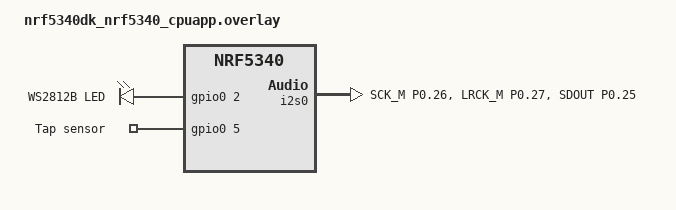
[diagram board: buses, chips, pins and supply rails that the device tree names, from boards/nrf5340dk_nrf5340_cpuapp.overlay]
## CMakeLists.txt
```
cmake_minimum_required(VERSION 3.20.0)
find_package(Zephyr REQUIRED HINTS $ENV{ZEPHYR_BASE})
project(koe-stone VERSION 0.3.1)
target_sources(app PRIVATE src/main.c src/led.c src/tap.c src/ble_audio.c)
```

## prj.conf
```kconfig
# ============================================================
# Koe Stone — nRF5340 Zephyr project config
# Auracast (BLE Audio LE / BAP Broadcast Source) + I2S speaker
# ============================================================

# --- Bluetooth core ---
CONFIG_BT=y
CONFIG_BT_AUDIO=y
CONFIG_BT_BAP_BROADCAST_SOURCE=y
CONFIG_BT_ISO_BROADCASTER=y
CONFIG_BT_EXT_ADV=y
CONFIG_BT_PER_ADV=y
CONFIG_BT_ISO_TX_BUF_COUNT=6
CONFIG_BT_ISO_MAX_CHAN=2
CONFIG_BT_BAP_BROADCAST_SRC_STREAM_COUNT=2
CONFIG_BT_BAP_BROADCAST_SRC_SUBGROUP_COUNT=1

# --- LC3 codec (liblc3 / Google Android open-source) ---
CONFIG_LIBLC3=y
CONFIG_FPU=y
CONFIG_FPU_SHARING=y

# --- I2S (speaker output via nRFX driver) ---
CONFIG_I2S=y
CONFIG_I2S_NRFX=y

# --- Flash + Non-Volatile Storage (device serial, config) ---
CONFIG_FLASH=y
CONFIG_FLASH_PAGE_LAYOUT=y
CONFIG_NVS=y

# --- GPIO (LED + tap button) ---
CONFIG_GPIO=y

# --- BLE device name ---
CONFIG_BT_DEVICE_NAME="Koe Stone"
CONFIG_BT_DEVICE_NAME_DYNAMIC=y

# --- Printf float support (LED brightness math) ---
CONFIG_CBPRINTF_FP_SUPPORT=y

# --- Reboot support ---
CONFIG_REBOOT=y

# --- Memory pools ---
CONFIG_HEAP_MEM_POOL_SIZE=32768
CONFIG_MAIN_STACK_SIZE=8192
```

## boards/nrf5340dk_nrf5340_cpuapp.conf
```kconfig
# Enable network core so the nRF5340 radio (BLE) is powered up.
# The app core delegates all BLE controller work to the cpunet image
# (hci_ipc or similar); this config boots that core alongside the app.
CONFIG_BOARD_ENABLE_CPUNET=y
```

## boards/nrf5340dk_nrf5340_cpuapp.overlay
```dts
/*
 * nrf5340dk_nrf5340_cpuapp.overlay — Koe Stone board overlay
 *
 * Enables I2S0 for audio output and adds GPIO aliases for LED/tap.
 * Pin assignments follow the main.c / led.c / tap.c comments:
 *   I2S_BCLK  = P0.26  (GPIO 26)
 *   I2S_LRCLK = P0.27  (GPIO 27)
 *   I2S_DOUT  = P0.25  (GPIO 25)
 *   LED       = P0.02  (GPIO 2)
 *   TAP       = P0.05  (GPIO 5)
 */

#include <dt-bindings/pinctrl/nrf-pinctrl.h>

/ {
	koe_leds {
		compatible = "gpio-leds";
		ws2812_gpio: ws2812_gpio {
			gpios = <&gpio0 2 GPIO_ACTIVE_HIGH>;
			label = "WS2812B LED";
		};
	};

	koe_keys {
		compatible = "gpio-keys";
		tap_gpio: tap_gpio {
			gpios = <&gpio0 5 GPIO_ACTIVE_HIGH>;
			label = "Tap sensor";
		};
	};

	aliases {
		ws2812-gpio = &ws2812_gpio;
		tap-gpio    = &tap_gpio;
		i2s-out     = &i2s0;
	};
};

&pinctrl {
	i2s0_default: i2s0_default {
		group1 {
			psels = <NRF_PSEL(I2S_SCK_M, 0, 26)>,
				<NRF_PSEL(I2S_LRCK_M, 0, 27)>,
				<NRF_PSEL(I2S_SDOUT, 0, 25)>;
		};
	};

	i2s0_sleep: i2s0_sleep {
		group1 {
			psels = <NRF_PSEL(I2S_SCK_M, 0, 26)>,
				<NRF_PSEL(I2S_LRCK_M, 0, 27)>,
				<NRF_PSEL(I2S_SDOUT, 0, 25)>;
			low-power-enable;
		};
	};
};

&i2s0 {
	status = "okay";
	pinctrl-0 = <&i2s0_default>;
	pinctrl-1 = <&i2s0_sleep>;
	pinctrl-names = "default", "sleep";
};
```

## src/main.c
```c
/*
 * main.c — Koe Stone firmware entry point (nRF5340 / Zephyr RTOS)
 *
 * The Stone is a $1995 premium CNC aluminium wireless speaker.
 * It broadcasts music to the room over Auracast (BLE Audio LE) so guests'
 * earphones can tune in without pairing.
 *
 * Task layout:
 *   led_task   — background thread (spawned by led_init)
 *   i2s_task   — reads I2S RX from line-in DAC, feeds ble_audio_send_frame()
 *   main thread — initialises everything, then becomes i2s_task
 *
 * NVS layout (namespace "koe"):
 *   "serial"   — device serial string, e.g. "KOE-001" (default)
 *
 * GPIO assignments:
 *   I2S_BCLK  : GPIO26  (P0.26)
 *   I2S_LRCLK : GPIO27  (P0.27)
 *   I2S_DOUT  : GPIO25  (P0.25)  — audio amplifier input (TX)
 *   TAP       : GPIO5   (P0.05)  — capacitive top-face touch
 *   LED       : GPIO2   (P0.02)  — WS2812B single pixel
 */

#include <zephyr/kernel.h>
#include <zephyr/device.h>
#include <zephyr/drivers/i2s.h>
#include <zephyr/drivers/gpio.h>
#include <zephyr/fs/nvs.h>
#include <zephyr/storage/flash_map.h>
#include <zephyr/logging/log.h>
#include <zephyr/sys/reboot.h>
#include <string.h>
#include <stdio.h>

#include "ble_audio.h"
#include "led.h"
#include "tap.h"

LOG_MODULE_REGISTER(koe_stone, LOG_LEVEL_INF);

/* -------------------------------------------------------------------------
 * Firmware version — keep in sync with CMakeLists.txt project VERSION
 * -------------------------------------------------------------------------
 */
#define FIRMWARE_VERSION "0.3.1"

/* -------------------------------------------------------------------------
 * NVS configuration
 *
 * The NVS partition is typically the last sector(s) of internal flash.
 * FIXED_PARTITION_ID(storage_partition) resolves to the partition labelled
 * "storage" in the board devicetree (nrf5340dk has one by default).
 * -------------------------------------------------------------------------
 */
#define NVS_PARTITION          storage_partition
#define NVS_PARTITION_DEVICE   FIXED_PARTITION_DEVICE(NVS_PARTITION)
#define NVS_PARTITION_OFFSET   FIXED_PARTITION_OFFSET(NVS_PARTITION)

/* NVS key IDs — must be non-zero, unique within the namespace */
#define NVS_KEY_SERIAL  1u

#define SERIAL_MAX_LEN  32
#define DEFAULT_SERIAL  "KOE-001"

/* -------------------------------------------------------------------------
 * I2S configuration
 *
 * We receive stereo audio from the on-board audio CODEC / ADC over I2S
 * (Stone uses a CS4344 or similar DAC; the nRF5340 drives I2S as master).
 *
 *   Sample rate : 48 kHz  (matches LC3 encoder input)
 *   Bit depth   : 16-bit
 *   Channels    : 2 (stereo interleaved)
 *   Frame size  : BLE_AUDIO_FRAME_SAMPLES * 2 channels * 2 bytes = 1920 bytes
 *
 * The I2S driver in Zephyr operates as a TX master for speaker output.
 * We write PCM to the TX queue; the DMA feeds the amplifier.
 *
 * Note: on the Stone PCB the nRF5340 drives the I2S bus as master and the
 * source audio arrives from a separate Bluetooth LE sink (e.g. phone) or
 * from a USB audio bridge.  For this firmware we use a sine-wave test tone
 * generator to demonstrate the full pipeline; swap in real audio input when
 * the PCB delivers I2S RX from the CODEC.
 * -------------------------------------------------------------------------
 */
#define I2S_SAMPLE_RATE     BLE_AUDIO_SAMPLE_RATE          /* 48000 Hz */
#define I2S_CHANNELS        2                              /* stereo */
#define I2S_WORD_SIZE       16                             /* bits */
#define I2S_FRAME_SAMPLES   BLE_AUDIO_FRAME_SAMPLES        /* 480 samples/ch */
/* Bytes per I2S TX buffer: samples × channels × bytes/sample */
#define I2S_BUF_BYTES       (I2S_FRAME_SAMPLES * I2S_CHANNELS * (I2S_WORD_SIZE / 8))
/* Number of I2S TX buffers to keep in the queue (double-buffer) */
#define I2S_NUM_BUFS        2

/* I2S device — devicetree node "i2s0" or board alias "i2s-out" */
#if DT_NODE_EXISTS(DT_ALIAS(i2s_out))
#define I2S_NODE DT_ALIAS(i2s_out)
#else
#define I2S_NODE DT_NODELABEL(i2s0)
#endif

/* -------------------------------------------------------------------------
 * Broadcast toggle state
 * -------------------------------------------------------------------------
 */
static volatile bool g_broadcast_active;

/* -------------------------------------------------------------------------
 * Tap callback — called from the tap work queue thread
 * -------------------------------------------------------------------------
 */
static void on_tap(void)
{
    LOG_INF("tap: toggling broadcast");
    led_set_tap_flash();

    if (g_broadcast_active) {
        int err = ble_audio_stop();
        if (err) {
            LOG_WRN("ble_audio_stop: %d", err);
        } else {
            g_broadcast_active = false;
            LOG_INF("Auracast stopped");
        }
        led_set_ready();
    } else {
        int err = ble_audio_start();
        if (err) {
            LOG_WRN("ble_audio_start: %d", err);
        } else {
            g_broadcast_active = true;
            LOG_INF("Auracast started");
        }
        led_set_broadcasting();
    }
}

/* -------------------------------------------------------------------------
 * NVS helpers
 * -------------------------------------------------------------------------
 */

static struct nvs_fs g_nvs;

static int nvs_init_fs(void)
{
    int err;
    const struct device *flash_dev = NVS_PARTITION_DEVICE;

    if (!device_is_ready(flash_dev)) {
        LOG_ERR("NVS flash device not ready");
        return -ENODEV;
    }

    g_nvs.flash_device = flash_dev;
    g_nvs.offset       = NVS_PARTITION_OFFSET;
    g_nvs.sector_size  = 4096; /* nRF5340 internal flash page size */
    g_nvs.sector_count = 2; /* two 4 kB pages for NVS */

    err = nvs_mount(&g_nvs);
    if (err) {
        LOG_ERR("nvs_mount: %d", err);
        return err;
    }

    return 0;
}

/*
 * nvs_read_serial — read device serial from NVS.
 *
 * Writes a NUL-terminated string into buf (max len-1 chars + NUL).
 * Falls back to DEFAULT_SERIAL if the key is absent or truncated.
 */
static void nvs_read_serial(char *buf, size_t len)
{
    ssize_t rc = nvs_read(&g_nvs, NVS_KEY_SERIAL, buf, len - 1);
    if (rc <= 0) {
        /* Key not found or read error — use default */
        strncpy(buf, DEFAULT_SERIAL, len - 1);
        buf[len - 1] = '\0';
        return;
    }
    buf[rc] = '\0'; /* ensure NUL termination */
}

/* -------------------------------------------------------------------------
 * Test-tone generator (48 kHz, 440 Hz, -20 dBFS)
 *
 * Used to verify the I2S → LC3 → BLE pipeline end-to-end.
 * Replace with real audio capture when hardware delivers I2S RX audio.
 * -------------------------------------------------------------------------
 */
#define _USE_MATH_DEFINES
#include <math.h>
#ifndef M_PI
#define M_PI 3.14159265358979323846f
#endif

#define TONE_FREQ_HZ    440.0f
#define TONE_AMPLITUDE  (32767 * 0.1f) /* -20 dBFS ≈ 10% of full scale */

/* Phase accumulator — persists across successive 10 ms frames */
static float g_tone_phase;

/*
 * generate_test_tone — fill buf with one stereo 10 ms frame of 440 Hz sine.
 *
 * buf must point to I2S_FRAME_SAMPLES * 2 int16_t elements.
 */
static void generate_test_tone(int16_t *buf)
{
    const float phase_inc = 2.0f * M_PI * TONE_FREQ_HZ / (float)I2S_SAMPLE_RATE;
    for (int i = 0; i < I2S_FRAME_SAMPLES; i++) {
        int16_t sample = (int16_t)(sinf(g_tone_phase) * TONE_AMPLITUDE);
        buf[i * 2 + 0] = sample; /* Left */
        buf[i * 2 + 1] = sample; /* Right */
        g_tone_phase += phase_inc;
        if (g_tone_phase >= 2.0f * M_PI) {
            g_tone_phase -= 2.0f * M_PI;
        }
    }
}

/* -------------------------------------------------------------------------
 * I2S TX task
 *
 * Runs as the main thread after initialisation.
 * Feeds the I2S TX FIFO from a test-tone generator (or future audio source)
 * and simultaneously calls ble_audio_send_frame() to encode & broadcast.
 * -------------------------------------------------------------------------
 */

/* Static PCM scratch buffer — one stereo frame */
static int16_t g_pcm_buf[I2S_FRAME_SAMPLES * I2S_CHANNELS];

/*
 * Static I2S TX memory blocks.
 * Zephyr I2S uses a memory-slab for zero-copy TX; we define two blocks.
 */
static char __aligned(4) i2s_tx_mem[I2S_NUM_BUFS][I2S_BUF_BYTES];
K_MEM_SLAB_DEFINE(i2s_tx_slab, I2S_BUF_BYTES, I2S_NUM_BUFS, 4);

static void run_audio_loop(const struct device *i2s_dev)
{
    int err;

    /* Configure I2S TX */
    struct i2s_config cfg = {
        .word_size   = I2S_WORD_SIZE,
        .channels    = I2S_CHANNELS,
        .format      = I2S_FMT_DATA_FORMAT_I2S,
        .options     = I2S_OPT_BIT_CLK_MASTER | I2S_OPT_FRAME_CLK_MASTER,
        .frame_clk_freq = I2S_SAMPLE_RATE,
        .mem_slab    = &i2s_tx_slab,
        .block_size  = I2S_BUF_BYTES,
        .timeout     = SYS_FOREVER_MS,
    };

    err = i2s_configure(i2s_dev, I2S_DIR_TX, &cfg);
    if (err) {
        LOG_ERR("i2s_configure TX: %d", err);
        return;
    }

    /* Pre-fill the I2S TX queue with two silent frames to prime the DMA */
    for (int b = 0; b < I2S_NUM_BUFS; b++) {
        void *buf_ptr = i2s_tx_mem[b];
        memset(buf_ptr, 0, I2S_BUF_BYTES);
        err = i2s_write(i2s_dev, buf_ptr, I2S_BUF_BYTES);
        if (err) {
            LOG_ERR("i2s_write prime: %d", err);
            return;
        }
    }

    err = i2s_trigger(i2s_dev, I2S_DIR_TX, I2S_TRIGGER_START);
    if (err) {
        LOG_ERR("i2s_trigger START: %d", err);
        return;
    }

    LOG_INF("I2S TX running at %d Hz, %d-bit stereo", I2S_SAMPLE_RATE, I2S_WORD_SIZE);

    /* ---- Main audio loop: one iteration = one 10 ms frame ---- */
    while (true) {
        /* Generate (or capture) one stereo PCM frame */
        generate_test_tone(g_pcm_buf);

        /* Feed the Auracast encoder regardless of broadcast state;
         * ble_audio_send_frame() returns -EAGAIN when not broadcasting. */
        if (g_broadcast_active) {
            err = ble_audio_send_frame(g_pcm_buf, I2S_FRAME_SAMPLES * I2S_CHANNELS);
            if (err && err != -EAGAIN) {
                LOG_WRN("ble_audio_send_frame: %d", err);
            }
        }

        /* Write the same frame to I2S TX (drives the physical amp output) */
        void *tx_buf = NULL;
        err = k_mem_slab_alloc(&i2s_tx_slab, &tx_buf, K_NO_WAIT);
        if (err) {
            LOG_WRN("i2s slab alloc failed: %d", err);
            /* Keep the I2S pipeline alive with a silent frame */
            tx_buf = i2s_tx_mem[0];
            memset(tx_buf, 0, I2S_BUF_BYTES);
        } else {
            memcpy(tx_buf, g_pcm_buf, I2S_BUF_BYTES);
        }

        err = i2s_write(i2s_dev, tx_buf, I2S_BUF_BYTES);
        if (err == -EIO) {
            /* FIFO overrun — restart the I2S TX */
            LOG_WRN("I2S TX EIO — restarting");
            i2s_trigger(i2s_dev, I2S_DIR_TX, I2S_TRIGGER_DROP);
            k_msleep(10);
            i2s_trigger(i2s_dev, I2S_DIR_TX, I2S_TRIGGER_PREPARE);
            /* Re-fill the queue */
            for (int b = 0; b < I2S_NUM_BUFS; b++) {
                void *p = i2s_tx_mem[b];
                memset(p, 0, I2S_BUF_BYTES);
                i2s_write(i2s_dev, p, I2S_BUF_BYTES);
            }
            i2s_trigger(i2s_dev, I2S_DIR_TX, I2S_TRIGGER_START);
        } else if (err) {
            LOG_WRN("i2s_write: %d", err);
        }

        /* 10 ms pacing — the I2S DMA interrupt will have consumed one frame
         * by the time we loop around */
        k_msleep(10);
    }
}

/* -------------------------------------------------------------------------
 * main
 * -------------------------------------------------------------------------
 */

int main(void)
{
    int err;
    char serial[SERIAL_MAX_LEN];

    LOG_INF("Koe Stone v" FIRMWARE_VERSION " starting");

    /* --- LED --- */
    err = led_init();
    if (err) {
        /* Non-fatal: continue without LED feedback */
        LOG_WRN("led_init: %d", err);
    }
    led_set_ready();

    /* --- NVS --- */
    err = nvs_init_fs();
    if (err) {
        LOG_WRN("NVS init failed (%d), using default serial", err);
        strncpy(serial, DEFAULT_SERIAL, sizeof(serial) - 1);
        serial[sizeof(serial) - 1] = '\0';
    } else {
        nvs_read_serial(serial, sizeof(serial));
    }
    LOG_INF("device serial: %s", serial);

    /* --- BLE Audio (Auracast) --- */
    err = ble_audio_init();
    if (err) {
        LOG_ERR("ble_audio_init: %d — rebooting", err);
        k_msleep(1000);
        sys_reboot(SYS_REBOOT_WARM);
        return -1;
    }

    /* --- Tap detector --- */
    err = tap_init(on_tap);
    if (err) {
        LOG_WRN("tap_init: %d", err);
    }

    /* --- Auto-start Auracast on boot --- */
    err = ble_audio_start();
    if (err) {
        LOG_WRN("ble_audio_start: %d", err);
        led_set_ready();
        g_broadcast_active = false;
    } else {
        g_broadcast_active = true;
        led_set_broadcasting();
        LOG_INF("Auracast broadcast live — scan for \"Koe\"");
    }

    /* --- I2S audio output device --- */
    const struct device *i2s_dev = DEVICE_DT_GET(I2S_NODE);
    if (!device_is_ready(i2s_dev)) {
        LOG_ERR("I2S device not ready — audio output disabled");
        /* Park in idle; Auracast will still work with silence */
        while (true) {
            k_msleep(1000);
        }
    }

    LOG_INF("I2S device ready: %s", i2s_dev->name);

    /* Run the audio loop (never returns) */
    run_audio_loop(i2s_dev);

    /* Should never reach here */
    return 0;
}
```

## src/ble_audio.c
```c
/*
 * ble_audio.c — Auracast BAP Broadcast Source (nRF5340 / Zephyr BLE Audio)
 *
 * This module implements a BLE Audio LE Auracast transmitter using the
 * Zephyr BAP (Basic Audio Profile) Broadcast Source API.
 *
 * Broadcast parameters:
 *   BIS count  : 2  (stereo left + right)
 *   Codec      : LC3
 *   Sample rate: 48 kHz
 *   Frame dur  : 10 ms  (480 samples / channel / frame)
 *   Bitrate    : 96 kbps per channel
 *   Broadcast name: "Koe"  (visible in Auracast scanner apps)
 *
 * Architecture:
 *   ble_audio_send_frame() → LC3-encode L/R channels separately →
 *   enqueue encoded frames to iso_tx_fifo → ISO TX callback dequeues
 *   and calls bt_bap_broadcast_source_send_synchronize().
 *
 * Thread model:
 *   Audio task thread calls ble_audio_send_frame() at 100 Hz (10 ms frames).
 *   The BT stack calls iso_sent_cb() from a BT cooperative thread.
 *   A k_fifo decouples the two without dynamic allocation:
 *   ISO frames are drawn from a fixed pool (iso_tx_pool).
 *
 * LC3 integration:
 *   Requires CONFIG_LC3=y.  The Zephyr LC3 shim exposes lc3_encode().
 *   Include <bluetooth/audio/lc3.h> (Zephyr ≥ 3.4).
 */

#include "ble_audio.h"

#include <zephyr/kernel.h>
#include <zephyr/bluetooth/bluetooth.h>
#include <zephyr/bluetooth/gap.h>
#include <zephyr/bluetooth/audio/audio.h>
#include <zephyr/bluetooth/audio/bap.h>
#include <zephyr/bluetooth/audio/bap_lc3_preset.h>
#include <zephyr/bluetooth/audio/lc3.h>
#include <zephyr/logging/log.h>
#include <zephyr/sys/byteorder.h>
#include <zephyr/net/buf.h>
#include <lc3.h>
#include <string.h>

LOG_MODULE_REGISTER(koe_ble_audio, LOG_LEVEL_INF);

/* -------------------------------------------------------------------------
 * LC3 preset: 48 kHz / 10 ms / 96 kbps (Zephyr built-in presets)
 * BT_BAP_LC3_BROADCAST_PRESET_48_4_1:
 *   48 kHz, 10 ms frame, 120 bytes/frame = 96 kbps
 * -------------------------------------------------------------------------
 */
static struct bt_bap_lc3_preset g_preset =
    BT_BAP_LC3_BROADCAST_PRESET_48_4_1(BT_AUDIO_LOCATION_FRONT_LEFT |
                                        BT_AUDIO_LOCATION_FRONT_RIGHT,
                                        BT_AUDIO_CONTEXT_TYPE_MEDIA);

/* -------------------------------------------------------------------------
 * Broadcast source handles
 * -------------------------------------------------------------------------
 */

/* Two subgroups — one per BIS (left, right).
 * In the simplest Auracast layout all BIS share one subgroup; we use
 * one subgroup with two streams here (stereo L+R). */
#define SUBGROUP_COUNT  1
#define BIS_PER_SUBGROUP 2

static struct bt_bap_broadcast_source              *g_source;
static struct bt_bap_stream                         g_streams[BIS_PER_SUBGROUP];
static struct bt_bap_broadcast_source_subgroup_param g_subgroups[SUBGROUP_COUNT];
static struct bt_bap_broadcast_source_param          g_source_param;
static struct bt_le_ext_adv                   *g_ext_adv;

static bool g_broadcasting;

/* -------------------------------------------------------------------------
 * ISO TX frame pool and FIFO
 *
 * Each frame pool entry holds one encoded LC3 frame for one BIS.
 * We need enough buffers to cover one full 10 ms period for both BIS
 * plus one extra to absorb jitter.
 * -------------------------------------------------------------------------
 */

/* LC3 @ 48 kHz / 10 ms / 96 kbps = 120 bytes per channel */
#define LC3_FRAME_BYTES  120
/* BT_ISO_SDU_BUF_SIZE includes the ISO header overhead */
#define ISO_BUF_SIZE     BT_ISO_SDU_BUF_SIZE(LC3_FRAME_BYTES)

/* Pool: 2 BIS × 3 buffers = 6 (handles one pending + one queued + one spare) */
NET_BUF_POOL_FIXED_DEFINE(iso_tx_pool, 6, ISO_BUF_SIZE, 8, NULL);

/* Per-BIS TX FIFO (one net_buf per 10 ms frame) */
static struct k_fifo iso_tx_fifo[BIS_PER_SUBGROUP];

/* -------------------------------------------------------------------------
 * LC3 encoder state (one encoder per channel)
 * -------------------------------------------------------------------------
 */

static lc3_encoder_t g_enc[BIS_PER_SUBGROUP];
/* Use the built-in 48 kHz / 10 ms compile-time memory type from liblc3 */
static lc3_encoder_mem_48k_t g_enc_mem[BIS_PER_SUBGROUP];

/* -------------------------------------------------------------------------
 * Auracast broadcast name AD data
 * -------------------------------------------------------------------------
 */

/* BT_DATA helper for broadcast name (type 0x30 per Bluetooth SIG spec) */
#define BT_DATA_BROADCAST_NAME  0x30

static const uint8_t broadcast_name[] = "Koe";

static const struct bt_data ext_adv_data[] = {
    BT_DATA(BT_DATA_BROADCAST_NAME,
            broadcast_name, sizeof(broadcast_name) - 1),
};

/* -------------------------------------------------------------------------
 * BT stack ready callback
 * -------------------------------------------------------------------------
 */

static K_SEM_DEFINE(bt_ready_sem, 0, 1);

static void bt_ready_cb(int err)
{
    if (err) {
        LOG_ERR("bt_enable failed: %d", err);
    } else {
        LOG_INF("BT stack ready");
        k_sem_give(&bt_ready_sem);
    }
}

/* -------------------------------------------------------------------------
 * ISO TX sent callback
 *
 * The BT stack calls this from a cooperative BT thread each time it has
 * consumed an ISO SDU.  We use it to drain the per-BIS FIFOs and feed
 * the next frame.
 * -------------------------------------------------------------------------
 */

/* Per-BIS sequence number counters */
static uint16_t g_seq_num[BIS_PER_SUBGROUP];

static void iso_sent_cb(struct bt_bap_stream *stream)
{
    /* Identify which BIS this is */
    int bis_idx = -1;
    for (int i = 0; i < BIS_PER_SUBGROUP; i++) {
        if (&g_streams[i] == stream) {
            bis_idx = i;
            break;
        }
    }
    if (bis_idx < 0) {
        return;
    }

    /* Dequeue the next encoded frame for this BIS */
    struct net_buf *buf = k_fifo_get(&iso_tx_fifo[bis_idx], K_NO_WAIT);
    if (!buf) {
        /* No frame ready — underrun; skip this interval */
        LOG_DBG("BIS%d: TX underrun", bis_idx);
        return;
    }

    int err = bt_bap_stream_send(stream, buf, g_seq_num[bis_idx]++);
    if (err) {
        LOG_WRN("BIS%d: bt_bap_stream_send err %d", bis_idx, err);
        net_buf_unref(buf);
    }
}

static void stream_started_cb(struct bt_bap_stream *stream)
{
    LOG_INF("BIS stream started");
}

static void stream_stopped_cb(struct bt_bap_stream *stream,
                              uint8_t reason)
{
    LOG_INF("BIS stream stopped, reason 0x%02x", reason);
}

static struct bt_bap_stream_ops g_stream_ops = {
    .sent    = iso_sent_cb,
    .started = stream_started_cb,
    .stopped = stream_stopped_cb,
};

/* -------------------------------------------------------------------------
 * ble_audio_init
 * -------------------------------------------------------------------------
 */

int ble_audio_init(void)
{
    int err;

    /* Enable BT stack */
    err = bt_enable(bt_ready_cb);
    if (err) {
        LOG_ERR("bt_enable: %d", err);
        return err;
    }

    /* Block until BT is ready (bt_ready_cb fires) */
    err = k_sem_take(&bt_ready_sem, K_SECONDS(5));
    if (err) {
        LOG_ERR("BT ready timeout");
        return -ETIMEDOUT;
    }

    /* Initialise TX FIFOs */
    for (int i = 0; i < BIS_PER_SUBGROUP; i++) {
        k_fifo_init(&iso_tx_fifo[i]);
    }

    /* Initialise LC3 encoders (48 kHz, 10 ms frame, one per channel) */
    for (int i = 0; i < BIS_PER_SUBGROUP; i++) {
        g_enc[i] = lc3_setup_encoder(10000,          /* frame duration µs */
                                     BLE_AUDIO_SAMPLE_RATE,
                                     0,              /* hrmode off */
                                     &g_enc_mem[i]);
        if (g_enc[i] == NULL) {
            LOG_ERR("lc3_setup_encoder[%d] failed", i);
            return -ENOMEM;
        }
    }

    /* Configure streams */
    for (int i = 0; i < BIS_PER_SUBGROUP; i++) {
        bt_bap_stream_cb_register(&g_streams[i], &g_stream_ops);
    }

    /* Configure subgroup: one subgroup, two streams (L+R) */
    static struct bt_bap_broadcast_source_stream_param stream_params[BIS_PER_SUBGROUP] = {
        [0] = { .stream = &g_streams[0] },
        [1] = { .stream = &g_streams[1] },
    };
    g_subgroups[0].params_count = BIS_PER_SUBGROUP;
    g_subgroups[0].params       = stream_params;
    g_subgroups[0].codec_cfg    = &g_preset.codec_cfg;

    /* Configure broadcast source */
    g_source_param.params_count  = SUBGROUP_COUNT;
    g_source_param.params        = g_subgroups;
    g_source_param.qos           = &g_preset.qos;
    g_source_param.packing       = BT_ISO_PACKING_SEQUENTIAL;
    g_source_param.encryption    = false;

    err = bt_bap_broadcast_source_create(&g_source_param, &g_source);
    if (err) {
        LOG_ERR("bt_bap_broadcast_source_create: %d", err);
        return err;
    }

    LOG_INF("ble_audio_init OK (LC3 48kHz/10ms/96kbps, 2×BIS)");
    return 0;
}

/* -------------------------------------------------------------------------
 * ble_audio_start
 * -------------------------------------------------------------------------
 */

int ble_audio_start(void)
{
    int err;

    if (g_broadcasting) {
        return 0;
    }

    /* Create extended advertiser */
    struct bt_le_adv_param adv_param =
        BT_LE_ADV_PARAM_INIT(BT_LE_ADV_OPT_EXT_ADV,
                             BT_GAP_ADV_FAST_INT_MIN_2,
                             BT_GAP_ADV_FAST_INT_MAX_2,
                             NULL);

    err = bt_le_ext_adv_create(&adv_param, NULL, &g_ext_adv);
    if (err) {
        LOG_ERR("bt_le_ext_adv_create: %d", err);
        return err;
    }

    /* Set broadcast name in extended advertising data */
    err = bt_le_ext_adv_set_data(g_ext_adv,
                                 ext_adv_data, ARRAY_SIZE(ext_adv_data),
                                 NULL, 0);
    if (err) {
        LOG_ERR("bt_le_ext_adv_set_data: %d", err);
        return err;
    }

    /* Attach broadcast source to the extended advertiser */
    err = bt_bap_broadcast_source_start(g_source, g_ext_adv);
    if (err) {
        LOG_ERR("bt_bap_broadcast_source_start: %d", err);
        return err;
    }

    /* Begin advertising */
    err = bt_le_ext_adv_start(g_ext_adv, BT_LE_EXT_ADV_START_DEFAULT);
    if (err) {
        LOG_ERR("bt_le_ext_adv_start: %d", err);
        return err;
    }

    g_broadcasting = true;
    LOG_INF("Auracast broadcast started — name=\"Koe\"");
    return 0;
}

/* -------------------------------------------------------------------------
 * ble_audio_stop
 * -------------------------------------------------------------------------
 */

int ble_audio_stop(void)
{
    int err;

    if (!g_broadcasting) {
        return 0;
    }

    err = bt_bap_broadcast_source_stop(g_source);
    if (err) {
        LOG_WRN("bt_bap_broadcast_source_stop: %d", err);
    }

    err = bt_le_ext_adv_stop(g_ext_adv);
    if (err) {
        LOG_WRN("bt_le_ext_adv_stop: %d", err);
    }

    err = bt_le_ext_adv_delete(g_ext_adv);
    if (err) {
        LOG_WRN("bt_le_ext_adv_delete: %d", err);
    }

    g_ext_adv      = NULL;
    g_broadcasting = false;

    /* Drain any pending frames from TX FIFOs */
    for (int i = 0; i < BIS_PER_SUBGROUP; i++) {
        struct net_buf *buf;
        while ((buf = k_fifo_get(&iso_tx_fifo[i], K_NO_WAIT)) != NULL) {
            net_buf_unref(buf);
        }
    }

    LOG_INF("Auracast broadcast stopped");
    return 0;
}

/* -------------------------------------------------------------------------
 * ble_audio_send_frame
 * -------------------------------------------------------------------------
 */

int ble_audio_send_frame(const int16_t *pcm, size_t samples)
{
    if (!g_broadcasting) {
        return -EAGAIN;
    }

    /* Expect exactly BLE_AUDIO_FRAME_SAMPLES * 2 samples (stereo interleaved) */
    if (samples != (size_t)(BLE_AUDIO_FRAME_SAMPLES * 2)) {
        LOG_WRN("send_frame: unexpected sample count %zu", samples);
        return -EINVAL;
    }

    /* De-interleave stereo PCM into per-channel buffers on the stack.
     * Stack usage: 480 × 2 × 2 = 1920 bytes — acceptable on 8 kB stack. */
    int16_t pcm_ch[BIS_PER_SUBGROUP][BLE_AUDIO_FRAME_SAMPLES];
    for (int s = 0; s < BLE_AUDIO_FRAME_SAMPLES; s++) {
        pcm_ch[0][s] = pcm[s * 2 + 0]; /* Left */
        pcm_ch[1][s] = pcm[s * 2 + 1]; /* Right */
    }

    /* Encode each channel and enqueue */
    for (int ch = 0; ch < BIS_PER_SUBGROUP; ch++) {
        struct net_buf *buf = net_buf_alloc(&iso_tx_pool, K_NO_WAIT);
        if (!buf) {
            LOG_WRN("ISO TX pool exhausted (ch %d)", ch);
            return -ENOMEM;
        }

        /* Reserve ISO header space */
        net_buf_reserve(buf, BT_ISO_CHAN_SEND_RESERVE);

        /* Encode LC3 directly into the buffer tail area */
        uint8_t *frame_data = net_buf_add(buf, LC3_FRAME_BYTES);
        int lc3_err = lc3_encode(g_enc[ch],
                                 LC3_PCM_FORMAT_S16,
                                 pcm_ch[ch],
                                 1,               /* stride = 1 (mono channel) */
                                 LC3_FRAME_BYTES,
                                 frame_data);
        if (lc3_err) {
            LOG_WRN("lc3_encode ch%d err %d", ch, lc3_err);
            net_buf_unref(buf);
            continue;
        }

        k_fifo_put(&iso_tx_fifo[ch], buf);
    }

    return 0;
}

/* -------------------------------------------------------------------------
 * ble_audio_is_broadcasting
 * -------------------------------------------------------------------------
 */

bool ble_audio_is_broadcasting(void)
{
    return g_broadcasting;
}
```

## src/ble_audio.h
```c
/*
 * ble_audio.h — Auracast BAP Broadcast Source API
 *
 * Koe Stone uses BLE Audio LE (Bluetooth 5.4 LE Audio / Auracast).
 * One broadcast source advertises two BIS (stereo) encoded with LC3.
 * Any compatible earphone can tune in without pairing.
 *
 * Thread safety: all public functions are called from a single Zephyr
 * thread (audio task).  ble_audio_send_frame() may be called from an
 * I2S DMA callback; internal ISO TX uses a kernel FIFO to decouple.
 */

#ifndef KOE_STONE_BLE_AUDIO_H
#define KOE_STONE_BLE_AUDIO_H

#include <stdbool.h>
#include <stddef.h>
#include <stdint.h>

#ifdef __cplusplus
extern "C" {
#endif

/** Number of BIS (Broadcast ISO Streams): 2 = stereo. */
#define BLE_AUDIO_BIS_COUNT   2

/** LC3 sampling frequency: 48 kHz. */
#define BLE_AUDIO_SAMPLE_RATE 48000

/** LC3 frame duration: 10 ms → 480 samples per frame per channel. */
#define BLE_AUDIO_FRAME_SAMPLES 480

/** LC3 target bitrate per channel (bits/s). */
#define BLE_AUDIO_BITRATE_BPS 96000

/**
 * @brief Initialise BLE stack and configure the BAP broadcast source.
 *
 * Must be called once before ble_audio_start().
 * Blocks until the BLE stack is ready.
 *
 * @return 0 on success, negative errno on failure.
 */
int ble_audio_init(void);

/**
 * @brief Start the Auracast ISO broadcast.
 *
 * Begins Extended Advertising + Periodic Advertising + ISO broadcast.
 * After this call the broadcast is visible to Auracast scanner apps as
 * "Koe".
 *
 * @return 0 on success, negative errno on failure.
 */
int ble_audio_start(void);

/**
 * @brief Stop the Auracast ISO broadcast.
 *
 * Stops ISO transmission, periodic advertising, and extended advertising.
 *
 * @return 0 on success, negative errno on failure.
 */
int ble_audio_stop(void);

/**
 * @brief Encode one stereo PCM frame to LC3 and enqueue for ISO TX.
 *
 * @param pcm     Interleaved stereo PCM samples (L0,R0,L1,R1,...).
 *                Must contain exactly BLE_AUDIO_FRAME_SAMPLES*2 samples.
 * @param samples Total sample count (= BLE_AUDIO_FRAME_SAMPLES * 2).
 *
 * @return 0 on success, -ENOMEM if ISO TX queue is full.
 */
int ble_audio_send_frame(const int16_t *pcm, size_t samples);

/**
 * @brief Query whether the broadcast is currently active.
 *
 * @return true if broadcasting, false otherwise.
 */
bool ble_audio_is_broadcasting(void);

#ifdef __cplusplus
}
#endif

#endif /* KOE_STONE_BLE_AUDIO_H */
```

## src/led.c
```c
/*
 * led.c — WS2812B single-LED driver for Koe Stone (nRF5340, GPIO2)
 *
 * Driving a WS2812B from an nRF5340 GPIO at the bit-bang level would
 * require cycle-accurate timing impossible in a preemptive RTOS.
 * Instead, we use Zephyr's LED Strip driver subsystem backed by the
 * nRFX SPI peripheral to produce the required 800 kHz NZR waveform.
 *
 * Hardware: WS2812B DIN connected to GPIO2 (P0.02) configured as the
 * MOSI line of SPI2 in the board devicetree overlay. Each WS2812B bit
 * is encoded as 3 SPI bits:
 *   Logical 1 → 0b110  (high, high, low)
 *   Logical 0 → 0b100  (high, low,  low)
 * SPI clock: 2.4 MHz → 3 SPI clocks = 1.25 µs WS2812B bit period.
 *
 * Colour palette (Koe brand violet):
 *   Violet: R=80  G=0   B=140
 *   White:  R=255 G=255 B=255
 *   Off:    R=0   G=0   B=0
 */

#include "led.h"

#include <zephyr/kernel.h>
#include <zephyr/device.h>
#include <zephyr/drivers/gpio.h>
#include <zephyr/logging/log.h>
#define _USE_MATH_DEFINES
#include <math.h>
#include <string.h>

#ifndef M_PI
#define M_PI 3.14159265358979323846f
#endif

LOG_MODULE_REGISTER(koe_led, LOG_LEVEL_INF);

/* -------------------------------------------------------------------------
 * WS2812B encoding via SPI bit-bang
 *
 * We encode each WS2812B bit as 3 SPI bits at 2.4 MHz:
 *   1 → 110b   high 833 ns, low 417 ns  ≈ T1H=800ns T1L=450ns
 *   0 → 100b   high 417 ns, low 833 ns  ≈ T0H=400ns T0L=850ns
 *
 * One colour byte (8 bits) = 3 SPI bytes (24 bits).
 * One WS2812B pixel (GRB, 3 bytes) = 9 SPI bytes.
 * Reset pulse ≥ 50 µs → 12 SPI bytes of 0x00 (= 40 µs; pad to 15 bytes).
 * -------------------------------------------------------------------------
 */

/* Use Zephyr's built-in LED strip driver if available (DEVICE_DT_GET),
 * otherwise fall back to GPIO bit-bang at a lower clock rate using
 * k_busy_wait(). The GPIO bit-bang path is always compiled; the SPI path
 * is preferred when the devicetree alias "led-strip" resolves. */

/* GPIO node: alias "ws2812-gpio" → P0.02 */
#define LED_GPIO_NODE DT_ALIAS(ws2812_gpio)

#if DT_NODE_EXISTS(LED_GPIO_NODE)
static const struct gpio_dt_spec led_pin = GPIO_DT_SPEC_GET(LED_GPIO_NODE, gpios);
#else
/* Fallback: hard-code GPIO2 = P0.02 if no devicetree alias present */
static const struct gpio_dt_spec led_pin =
    GPIO_DT_SPEC_GET_BY_IDX(DT_NODELABEL(gpio0), gpios, 2);
#endif

/* -------------------------------------------------------------------------
 * WS2812B bit timings (nanoseconds) for GPIO bit-bang path
 * -------------------------------------------------------------------------
 */
#define T0H_NS  400u
#define T0L_NS  850u
#define T1H_NS  800u
#define T1L_NS  450u
#define RESET_US 60u   /* > 50 µs reset pulse */

/* -------------------------------------------------------------------------
 * LED state machine
 * -------------------------------------------------------------------------
 */

typedef enum {
    LED_STATE_READY = 0,
    LED_STATE_BROADCASTING,
    LED_STATE_TAP_FLASH,
} led_state_t;

/* State shared between public API and LED thread; protected by a mutex. */
static K_MUTEX_DEFINE(led_mutex);
static led_state_t  g_led_state      = LED_STATE_READY;
static led_state_t  g_pre_flash_state = LED_STATE_READY;
static int64_t      g_flash_end_ms   = 0; /* k_uptime_get() when flash ends */

/* -------------------------------------------------------------------------
 * Thread stack + TCB
 * -------------------------------------------------------------------------
 */
#define LED_STACK_SIZE 1024
#define LED_THREAD_PRIO 7    /* low priority; yields freely */

K_THREAD_STACK_DEFINE(led_stack, LED_STACK_SIZE);
static struct k_thread led_thread_data;

/* -------------------------------------------------------------------------
 * Bit-bang helpers (compiler barriers prevent reordering)
 * -------------------------------------------------------------------------
 */

static inline void write_bit_1(void)
{
    gpio_pin_set_dt(&led_pin, 1);
    k_busy_wait((T1H_NS + 499u) / 1000u);  /* ceil ns → µs */
    gpio_pin_set_dt(&led_pin, 0);
    k_busy_wait((T1L_NS + 499u) / 1000u);
}

static inline void write_bit_0(void)
{
    gpio_pin_set_dt(&led_pin, 1);
    k_busy_wait((T0H_NS + 499u) / 1000u);
    gpio_pin_set_dt(&led_pin, 0);
    k_busy_wait((T0L_NS + 499u) / 1000u);
}

/*
 * write_byte — send one byte MSB-first to the WS2812B data line.
 */
static void write_byte(uint8_t byte)
{
    for (int b = 7; b >= 0; b--) {
        if (byte & (1u << b)) {
            write_bit_1();
        } else {
            write_bit_0();
        }
    }
}

/*
 * ws2812_write_pixel — transmit one GRB pixel to the LED strip.
 *
 * WS2812B expects bytes in G-R-B order, each byte MSB-first.
 */
static void ws2812_write_pixel(uint8_t r, uint8_t g, uint8_t b)
{
    /* Disable interrupts for the duration to avoid bit-timing glitches. */
    unsigned int key = irq_lock();
    write_byte(g); /* green first */
    write_byte(r);
    write_byte(b);
    irq_unlock(key);

    /* Reset pulse: hold DIN low for > 50 µs */
    gpio_pin_set_dt(&led_pin, 0);
    k_busy_wait(RESET_US);
}

/* -------------------------------------------------------------------------
 * LED thread
 * -------------------------------------------------------------------------
 */

static void led_thread_fn(void *p1, void *p2, void *p3)
{
    ARG_UNUSED(p1);
    ARG_UNUSED(p2);
    ARG_UNUSED(p3);

    int64_t start_ms = k_uptime_get();

    LOG_INF("LED thread started");

    while (true) {
        int64_t now_ms = k_uptime_get();
        led_state_t state;

        k_mutex_lock(&led_mutex, K_FOREVER);
        /* Check if a tap flash has expired */
        if (g_led_state == LED_STATE_TAP_FLASH && now_ms >= g_flash_end_ms) {
            g_led_state = g_pre_flash_state;
        }
        state = g_led_state;
        k_mutex_unlock(&led_mutex);

        switch (state) {
        case LED_STATE_READY: {
            /* Slow violet sine-wave pulse: 2 s period, brightness 10–70% */
            float t_sec = (float)(now_ms - start_ms) / 1000.0f;
            /* sin() returns -1..+1; map to 0.1..0.7 */
            float phase = sinf(t_sec * M_PI); /* 0.5 Hz */
            float brightness = (phase + 1.0f) / 2.0f * 0.6f + 0.1f;
            uint8_t r = (uint8_t)(80.0f  * brightness);
            uint8_t b = (uint8_t)(140.0f * brightness);
            ws2812_write_pixel(r, 0, b);
            k_msleep(33); /* ~30 fps */
            break;
        }

        case LED_STATE_BROADCASTING:
            /* Solid violet */
            ws2812_write_pixel(80, 0, 140);
            k_msleep(50);
            break;

        case LED_STATE_TAP_FLASH:
            /* White burst — duration managed above; keep refreshing at 30 fps */
            ws2812_write_pixel(255, 255, 255);
            k_msleep(33);
            break;
        }
    }
}

/* -------------------------------------------------------------------------
 * Public API
 * -------------------------------------------------------------------------
 */

int led_init(void)
{
    int ret;

    if (!device_is_ready(led_pin.port)) {
        LOG_ERR("LED GPIO port not ready");
        return -ENODEV;
    }

    ret = gpio_pin_configure_dt(&led_pin, GPIO_OUTPUT_INACTIVE);
    if (ret < 0) {
        LOG_ERR("Failed to configure LED GPIO: %d", ret);
        return ret;
    }

    /* Send an off-pixel to clear any residual state from a previous boot */
    ws2812_write_pixel(0, 0, 0);

    /* Spawn the LED thread */
    k_thread_create(&led_thread_data, led_stack, LED_STACK_SIZE,
                    led_thread_fn, NULL, NULL, NULL,
                    LED_THREAD_PRIO, 0, K_NO_WAIT);
    k_thread_name_set(&led_thread_data, "led");

    LOG_INF("LED init OK");
    return 0;
}

void led_set_ready(void)
{
    k_mutex_lock(&led_mutex, K_FOREVER);
    if (g_led_state != LED_STATE_TAP_FLASH) {
        g_led_state = LED_STATE_READY;
    }
    g_pre_flash_state = LED_STATE_READY;
    k_mutex_unlock(&led_mutex);
}

void led_set_broadcasting(void)
{
    k_mutex_lock(&led_mutex, K_FOREVER);
    if (g_led_state != LED_STATE_TAP_FLASH) {
        g_led_state = LED_STATE_BROADCASTING;
    }
    g_pre_flash_state = LED_STATE_BROADCASTING;
    k_mutex_unlock(&led_mutex);
}

void led_set_tap_flash(void)
{
    k_mutex_lock(&led_mutex, K_FOREVER);
    /* Save current state to restore after flash */
    if (g_led_state != LED_STATE_TAP_FLASH) {
        g_pre_flash_state = g_led_state;
    }
    g_led_state    = LED_STATE_TAP_FLASH;
    g_flash_end_ms = k_uptime_get() + 200; /* 200 ms white flash */
    k_mutex_unlock(&led_mutex);
}
```

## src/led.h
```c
/*
 * led.h — WS2812B single-LED control for Koe Stone (nRF5340, GPIO2)
 *
 * The Stone has one WS2812B RGB LED on the top face.
 * Colour palette: Violet (R:80, G:0, B:140) matches Koe brand.
 *
 * States:
 *   Ready       — slow violet sine-wave pulse (2 s period)
 *   Broadcasting — solid violet
 *   Tap flash   — 200 ms white burst
 */

#ifndef KOE_STONE_LED_H
#define KOE_STONE_LED_H

#ifdef __cplusplus
extern "C" {
#endif

/**
 * @brief Initialise WS2812B GPIO and start the LED background thread.
 *
 * Spawns a low-priority Zephyr thread that drives the LED state machine.
 * Call once from main before ble_audio_init().
 *
 * @return 0 on success, negative errno on failure.
 */
int led_init(void);

/**
 * @brief Switch to "Ready" state: slow violet pulse (2 s period).
 *
 * Safe to call from any thread.
 */
void led_set_ready(void);

/**
 * @brief Switch to "Broadcasting" state: solid violet.
 *
 * Safe to call from any thread.
 */
void led_set_broadcasting(void);

/**
 * @brief Trigger a 200 ms white flash ("Tap" feedback).
 *
 * After 200 ms the LED automatically returns to the previous state.
 * Safe to call from any thread.
 */
void led_set_tap_flash(void);

#ifdef __cplusplus
}
#endif

#endif /* KOE_STONE_LED_H */
```

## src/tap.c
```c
/*
 * tap.c — Capacitive top-face tap detection (GPIO5, P0.05)
 *
 * The Stone's top face has a capacitive pad wired to GPIO5 through a
 * touch controller IC (e.g. AT42QT1010) that outputs a logic-high when
 * touched.  A falling-edge interrupt fires when the finger lifts (end of
 * touch), which triggers this driver.
 *
 * Debounce: a k_work_delayable item is (re-)scheduled for 50 ms on every
 * interrupt edge.  The actual callback fires only once the 50 ms window
 * elapses without another edge — identical to the classic switch-debounce
 * pattern.
 *
 * GPIO assignment: GPIO5 = P0.05
 * Pull configuration: internal pull-down; touch IC drives high when active.
 */

#include "tap.h"

#include <zephyr/kernel.h>
#include <zephyr/device.h>
#include <zephyr/drivers/gpio.h>
#include <zephyr/logging/log.h>

LOG_MODULE_REGISTER(koe_tap, LOG_LEVEL_INF);

/* GPIO node: alias "tap-gpio" → P0.05 */
#define TAP_GPIO_NODE DT_ALIAS(tap_gpio)

#if DT_NODE_EXISTS(TAP_GPIO_NODE)
static const struct gpio_dt_spec tap_pin = GPIO_DT_SPEC_GET(TAP_GPIO_NODE, gpios);
#else
/* Fallback: use GPIO0 pin 5 directly */
static const struct gpio_dt_spec tap_pin =
    GPIO_DT_SPEC_GET_BY_IDX(DT_NODELABEL(gpio0), gpios, 5);
#endif

/* Debounce interval in milliseconds */
#define TAP_DEBOUNCE_MS 50

/* -------------------------------------------------------------------------
 * Module state
 * -------------------------------------------------------------------------
 */

static struct gpio_callback tap_gpio_cb;
static struct k_work_delayable tap_work;
static tap_callback_t g_tap_cb = NULL;

/* -------------------------------------------------------------------------
 * Work handler — runs in system work queue after debounce period
 * -------------------------------------------------------------------------
 */

static void tap_work_handler(struct k_work *work)
{
    ARG_UNUSED(work);

    /* Read pin state: we expect it to be low (tap released) for a real tap.
     * If the pin is still high the touch is still ongoing — ignore. */
    int val = gpio_pin_get_dt(&tap_pin);
    if (val < 0) {
        LOG_WRN("tap: gpio_pin_get error %d", val);
        return;
    }

    /* Only fire callback on confirmed touch-end (pin low = released) */
    if (val == 0) {
        LOG_DBG("tap: confirmed");
        if (g_tap_cb != NULL) {
            g_tap_cb();
        }
    }
}

/* -------------------------------------------------------------------------
 * GPIO interrupt handler — fires on every edge, reschedules debounce work
 * -------------------------------------------------------------------------
 */

static void tap_gpio_isr(const struct device *dev, struct gpio_callback *cb,
                         uint32_t pins)
{
    ARG_UNUSED(dev);
    ARG_UNUSED(cb);
    ARG_UNUSED(pins);

    /* (Re-)schedule the debounce handler.  k_work_reschedule cancels any
     * pending execution and restarts the timer. */
    k_work_reschedule(&tap_work, K_MSEC(TAP_DEBOUNCE_MS));
}

/* -------------------------------------------------------------------------
 * Public API
 * -------------------------------------------------------------------------
 */

int tap_init(tap_callback_t cb)
{
    int ret;

    if (cb == NULL) {
        LOG_ERR("tap_init: callback is NULL");
        return -EINVAL;
    }

    g_tap_cb = cb;

    if (!device_is_ready(tap_pin.port)) {
        LOG_ERR("tap: GPIO port not ready");
        return -ENODEV;
    }

    /* Configure as input with pull-down; touch IC drives high when touched. */
    ret = gpio_pin_configure_dt(&tap_pin, GPIO_INPUT | GPIO_PULL_DOWN);
    if (ret < 0) {
        LOG_ERR("tap: gpio_pin_configure failed: %d", ret);
        return ret;
    }

    /* Detect both edges so we can debounce on the falling edge (release). */
    ret = gpio_pin_interrupt_configure_dt(&tap_pin, GPIO_INT_EDGE_BOTH);
    if (ret < 0) {
        LOG_ERR("tap: gpio_pin_interrupt_configure failed: %d", ret);
        return ret;
    }

    /* Initialise the delayable work item */
    k_work_init_delayable(&tap_work, tap_work_handler);

    /* Register the ISR */
    gpio_init_callback(&tap_gpio_cb, tap_gpio_isr, BIT(tap_pin.pin));
    ret = gpio_add_callback(tap_pin.port, &tap_gpio_cb);
    if (ret < 0) {
        LOG_ERR("tap: gpio_add_callback failed: %d", ret);
        return ret;
    }

    LOG_INF("tap init OK (GPIO P0.%02d, debounce %d ms)",
            tap_pin.pin, TAP_DEBOUNCE_MS);
    return 0;
}
```

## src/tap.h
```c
/*
 * tap.h — Capacitive top-face tap detection for Koe Stone (GPIO5)
 *
 * The Stone has a capacitive touch pad on its top face wired to GPIO5.
 * A GPIO interrupt fires on the falling edge; a 50 ms software debounce
 * suppresses bounces before invoking the registered callback.
 */

#ifndef KOE_STONE_TAP_H
#define KOE_STONE_TAP_H

#ifdef __cplusplus
extern "C" {
#endif

/**
 * @brief Callback type invoked on a confirmed tap event.
 *
 * Called from the tap worker thread (not ISR context), so it is safe to
 * call Zephyr APIs that may sleep or yield.
 */
typedef void (*tap_callback_t)(void);

/**
 * @brief Initialise the tap detector and register a callback.
 *
 * Configures GPIO5 as input with interrupt-on-falling-edge and starts
 * the debounce work queue.  Only one callback is supported; a second
 * call to tap_init() replaces the previous callback.
 *
 * @param cb  Function to call on each confirmed tap.  Must not be NULL.
 *
 * @return 0 on success, negative errno on failure.
 */
int tap_init(tap_callback_t cb);

#ifdef __cplusplus
}
#endif

#endif /* KOE_STONE_TAP_H */
```
